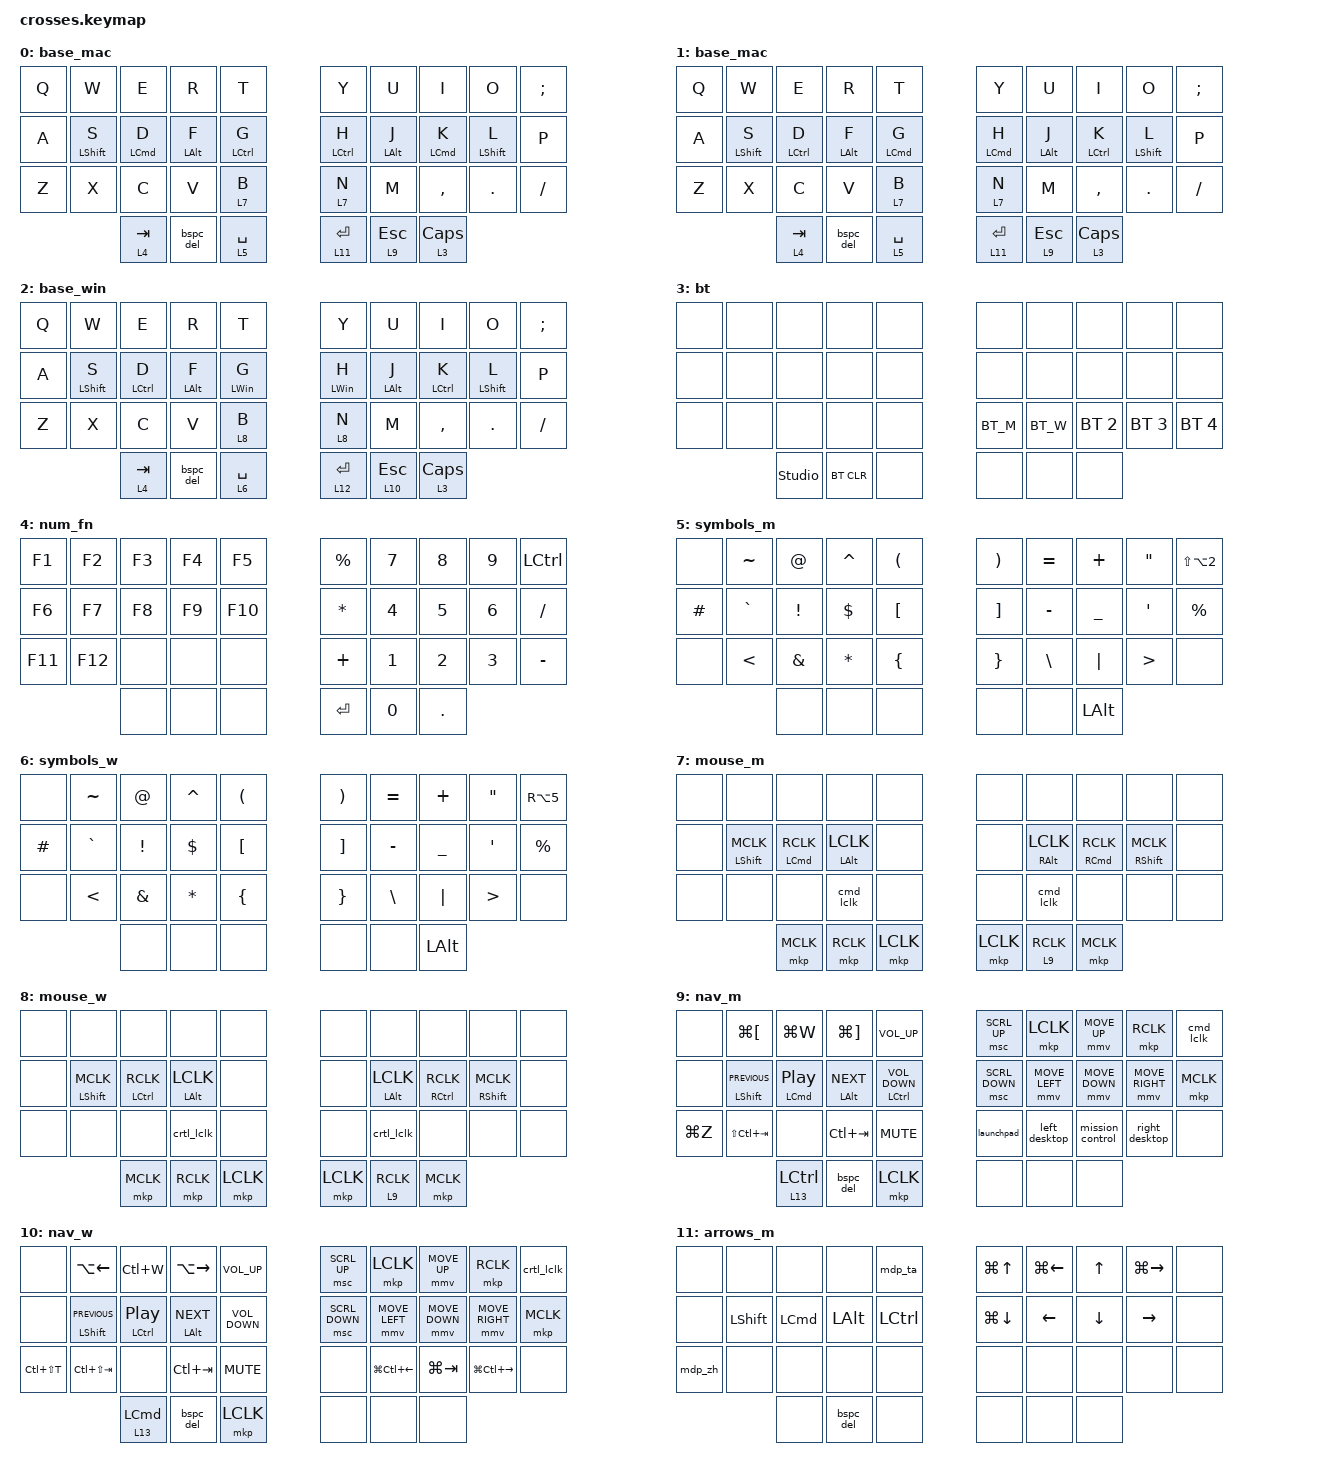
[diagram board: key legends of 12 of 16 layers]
/*
 * Copyright (c) 2020 The ZMK Contributors
 *
 * SPDX-License-Identifier: MIT
 */

#include <behaviors.dtsi>
#include <dt-bindings/zmk/bt.h>
#include <dt-bindings/zmk/keys.h>
#include <dt-bindings/zmk/pointing.h>

&caps_word { continue-list = <UNDERSCORE BACKSPACE DELETE RETURN SPACE>; };

/ {
    chosen { zmk,physical-layout = &gggw_crosses_36_layout; };

    combos {
        compatible = "zmk,combos";

        ctrl_alt_suppr {
            bindings = <&ctrl_alt_sppr>;
            key-positions = <7 3 2 6>;
            layers = <2 10>;
        };

        middle_click {
            bindings = <&mkp MCLK>;
            key-positions = <6 8>;
            layers = <9 10>;
        };

        base_mac_layer {
            bindings = <&to 0>;
            key-positions = <33 26>;
        };

        base_win_layer {
            bindings = <&to 2>;
            key-positions = <33 25>;
        };

        app_expose_m {
            bindings = <&app_expose>;
            key-positions = <27 26 28>;
            layers = <9>;
        };

        tog_micro {
            bindings = <&kp LG(LA(K))>;
            key-positions = <15 14>;
        };

        game_layer {
            bindings = <&to 15>;
            key-positions = <33 27>;
        };

        base_mac_vim {
            bindings = <&to 1>;
            key-positions = <33 25 26>;
        };
    };

    behaviors {
        hold_sitcky: hold_sitcky {
            compatible = "zmk,behavior-hold-tap";
            label = "HOLD_SITCKY";
            bindings = <&kp>, <&sk>;

            #binding-cells = <2>;
            tapping-term-ms = <200>;
            quick-tap-ms = <175>;
        };

        hold_to: hold_to {
            compatible = "zmk,behavior-hold-tap";
            label = "HOLD_TO";
            bindings = <&mo>, <&to>;

            #binding-cells = <2>;
            tapping-term-ms = <200>;
            quick-tap-ms = <175>;
            flavor = "balanced";
        };

        mo_sticky: mo_sticky {
            compatible = "zmk,behavior-hold-tap";
            label = "MO_STICKY";
            bindings = <&mo>, <&sk>;

            #binding-cells = <2>;
            tapping-term-ms = <200>;
            quick-tap-ms = <175>;
        };

        hmrl: hmrl {
            compatible = "zmk,behavior-hold-tap";
            label = "HMRL";
            bindings = <&kp>, <&kp>;

            #binding-cells = <2>;
            tapping-term-ms = <225>;
            quick-tap-ms = <200>;
            flavor = "tap-preferred";
        };

        hold_caps_word: hold_caps_word {
            compatible = "zmk,behavior-hold-tap";
            label = "HOLD_CAPS_WORD";
            bindings = <&mo>, <&kp>;

            #binding-cells = <2>;
            tapping-term-ms = <200>;
            quick-tap-ms = <175>;
            flavor = "balanced";
        };

        bspc_del: bspc_del {
            compatible = "zmk,behavior-mod-morph";
            label = "BSPC_DEL";
            bindings = <&kp BACKSPACE>, <&kp DELETE>;

            #binding-cells = <0>;
            mods = <(MOD_LSFT)>;
        };

        mo_mkp: mo_mkp {
            compatible = "zmk,behavior-hold-tap";
            label = "MO_MKP";
            bindings = <&mo>, <&mkp>;

            #binding-cells = <2>;
            tapping-term-ms = <200>;
            quick-tap-ms = <175>;
            flavor = "balanced";
        };

        hmr_mkp: hmr_mkp {
            compatible = "zmk,behavior-hold-tap";
            label = "HMR_MKP";
            bindings = <&kp>, <&mkp>;

            #binding-cells = <2>;
            tapping-term-ms = <225>;
            quick-tap-ms = <200>;
        };
    };

    macros {
        mission_control: mission_control {
            compatible = "zmk,behavior-macro";
            #binding-cells = <0>;
            bindings = <&kp LC(UP_ARROW)>;
            label = "Mission Control";
        };

        app_expose: app_expose {
            compatible = "zmk,behavior-macro";
            #binding-cells = <0>;
            bindings = <&kp LC(DOWN_ARROW)>;
            label = "App Expose";
        };

        left_desktop: left_desktop {
            compatible = "zmk,behavior-macro";
            #binding-cells = <0>;
            bindings = <&kp LC(LEFT_ARROW)>;
            label = "Left desktop";
        };

        right_desktop: right_desktop {
            compatible = "zmk,behavior-macro";
            #binding-cells = <0>;
            bindings = <&kp LC(RIGHT_ARROW)>;
            label = "Right desktop";
        };

        launchpad: launchpad {
            compatible = "zmk,behavior-macro";
            #binding-cells = <0>;
            bindings = <&kp LC(LS(UP_ARROW))>;
            label = "Launchpad";
        };

        ctrl_alt_sppr: ctrl_alt_sppr {
            compatible = "zmk,behavior-macro";
            #binding-cells = <0>;
            bindings = <&kp LA(LC(DELETE))>;
            label = "Ctrl+Alt+Suppr Windows";
        };

        start_line: start_line {
            compatible = "zmk,behavior-macro";
            #binding-cells = <0>;
            bindings = <&kp LG(LEFT_ARROW)>;
            label = "Start of line Mac";
        };

        end_line: end_line {
            compatible = "zmk,behavior-macro";
            #binding-cells = <0>;
            bindings = <&kp LG(RIGHT_ARROW)>;
            label = "End of line Mac";
        };

        BT_M: BT_M {
            compatible = "zmk,behavior-macro";
            #binding-cells = <0>;
            bindings = <&bt BT_SEL 0 &to 0>;
            label = "Bluetooth Mac";
        };

        BT_W: BT_W {
            compatible = "zmk,behavior-macro";
            #binding-cells = <0>;
            bindings = <&bt BT_SEL 1 &to 2>;
            label = "Bluetooth Windows";
        };

        cmd_lclk: cmd_lclk {
            compatible = "zmk,behavior-macro";
            #binding-cells = <0>;
            bindings =
                <&macro_press>,
                <&kp LEFT_COMMAND>,
                <&macro_tap>,
                <&mkp LCLK>,
                <&macro_release>,
                <&kp LEFT_COMMAND>;

            label = "Cmd+Left click";
        };

        crtl_lclk: crtl_lclk {
            compatible = "zmk,behavior-macro";
            #binding-cells = <0>;
            bindings =
                <&macro_press>,
                <&kp LEFT_CONTROL>,
                <&macro_tap>,
                <&mkp LCLK>,
                <&macro_release>,
                <&kp LEFT_CONTROL>;

            label = "Ctrl+Left click";
        };

        double_shift: double_shift {
            compatible = "zmk,behavior-macro";
            #binding-cells = <0>;
            bindings = <&kp LEFT_SHIFT &kp LEFT_SHIFT>;
            label = "DOUBLE_SHIFT";
        };

        mdp_zh: mdp_mac {
            compatible = "zmk,behavior-macro";
            #binding-cells = <0>;
            bindings = <&kp LS(Z) &kp A &kp H &kp A &kp LS(H) &kp A &kp D &kp I &kp D &kp N0 &kp N7 &kp EXCL>;
            label = "MDP_MAC";
        };

        mdp_ta: mdp_dash {
            compatible = "zmk,behavior-macro";
            #binding-cells = <0>;
            bindings = <&kp LS(T) &kp A &kp D &kp A &kp O &kp LS(A) &kp N &kp D &kp O &kp N0 &kp N7>;
            label = "MDP_DASH";
        };

        mdp_cap: mdp_cap {
            compatible = "zmk,behavior-macro";
            #binding-cells = <0>;
            bindings = <&kp LS(E) &kp S &kp M &kp E &kp E &kp LS(G) &kp U &kp I &kp L &kp L &kp O &kp U &kp N1 &kp N5 &kp EXCL>;
            label = "MDP_CAP";
        };
    };

    keymap {
        compatible = "zmk,keymap";

        base_mac {
            display-name = "base_mac";
            bindings = <
&kp Q  &kp W               &kp E                 &kp R             &kp T                 &kp Y                 &kp U             &kp I                 &kp O               &kp SEMICOLON
&kp A  &hmrl LEFT_SHIFT S  &hmrl LEFT_COMMAND D  &hmrl LEFT_ALT F  &hmrl LEFT_CONTROL G  &hmrl LEFT_CONTROL H  &hmrl LEFT_ALT J  &hmrl LEFT_COMMAND K  &hmrl LEFT_SHIFT L  &kp P
&kp Z  &kp X               &kp C                 &kp V             &lt 7 B               &lt 7 N               &kp M             &kp COMMA             &kp DOT             &kp FSLH
                           &lt 4 TAB             &bspc_del         &lt 5 SPACE           &lt 11 RETURN         &lt 9 ESCAPE      &lt 3 CAPSLOCK
            >;
        };

        base_mac_vim {
            display-name = "base_mac";
            bindings = <
&kp Q  &kp W               &kp E                 &kp R             &kp T                 &kp Y                 &kp U             &kp I                 &kp O               &kp SEMICOLON
&kp A  &hmrl LEFT_SHIFT S  &hmrl LEFT_CONTROL D  &hmrl LEFT_ALT F  &hmrl LEFT_COMMAND G  &hmrl LEFT_COMMAND H  &hmrl LEFT_ALT J  &hmrl LEFT_CONTROL K  &hmrl LEFT_SHIFT L  &kp P
&kp Z  &kp X               &kp C                 &kp V             &lt 7 B               &lt 7 N               &kp M             &kp COMMA             &kp DOT             &kp FSLH
                           &lt 4 TAB             &bspc_del         &lt 5 SPACE           &lt 11 RETURN         &lt 9 ESCAPE      &lt 3 CAPSLOCK
            >;

            label = "base_mac_vim";
        };

        base_win {
            display-name = "base_win";
            bindings = <
&kp Q  &kp W               &kp E                 &kp R             &kp T             &kp Y             &kp U             &kp I                 &kp O               &kp SEMICOLON
&kp A  &hmrl LEFT_SHIFT S  &hmrl LEFT_CONTROL D  &hmrl LEFT_ALT F  &hmrl LEFT_WIN G  &hmrl LEFT_WIN H  &hmrl LEFT_ALT J  &hmrl LEFT_CONTROL K  &hmrl LEFT_SHIFT L  &kp P
&kp Z  &kp X               &kp C                 &kp V             &lt 8 B           &lt 8 N           &kp M             &kp COMMA             &kp DOT             &kp FSLH
                           &lt 4 TAB             &bspc_del         &lt 6 SPACE       &lt 12 RETURN     &lt 10 ESCAPE     &lt 3 CAPSLOCK
            >;
        };

        bt {
            display-name = "bt";
            bindings = <
&none  &none  &none           &none       &none  &none  &none  &none         &none         &none
&none  &none  &none           &none       &none  &none  &none  &none         &none         &none
&none  &none  &none           &none       &none  &BT_M  &BT_W  &bt BT_SEL 2  &bt BT_SEL 3  &bt BT_SEL 4
              &studio_unlock  &bt BT_CLR  &none  &none  &none  &none
            >;
        };

        num_fn {
            display-name = "num_fn";
            bindings = <
&kp F1   &kp F2   &kp F3  &kp F4  &kp F5   &kp PERCENT   &kp N7        &kp N8      &kp N9  &kp LCTRL
&kp F6   &kp F7   &kp F8  &kp F9  &kp F10  &kp ASTERISK  &kp N4        &kp N5      &kp N6  &kp FSLH
&kp F11  &kp F12  &none   &none   &none    &kp PLUS      &kp N1        &kp N2      &kp N3  &kp MINUS
                  &none   &none   &none    &kp RET       &kp NUMBER_0  &kp PERIOD
            >;
        };

        symbols_m {
            display-name = "symbols_m";
            bindings = <
&none     &kp TILDE      &kp AT_SIGN      &kp CARET     &kp LEFT_PARENTHESIS  &kp RIGHT_PARENTHESIS  &kp EQUAL      &kp PLUS        &kp DOUBLE_QUOTES  &kp LS(LA(NUMBER_2))
&kp HASH  &kp GRAVE      &kp EXCLAMATION  &kp DOLLAR    &kp LEFT_BRACKET      &kp RIGHT_BRACKET      &kp MINUS      &kp UNDERSCORE  &kp APOSTROPHE     &kp PERCENT
&none     &kp LESS_THAN  &kp AMPERSAND    &kp ASTERISK  &kp LEFT_BRACE        &kp RIGHT_BRACE        &kp BACKSLASH  &kp PIPE        &kp GREATER_THAN   &none
                         &none            &none         &none                 &none                  &none          &kp LEFT_ALT
            >;
        };

        symbols_w {
            display-name = "symbols_w";
            bindings = <
&none     &kp TILDE      &kp AT           &kp CARET     &kp LEFT_PARENTHESIS  &kp RIGHT_PARENTHESIS  &kp EQUAL  &kp PLUS        &kp DOUBLE_QUOTES  &kp RA(NUMBER_5)
&kp HASH  &kp GRAVE      &kp EXCLAMATION  &kp DOLLAR    &kp LBKT              &kp RBKT               &kp MINUS  &kp UNDERSCORE  &kp APOSTROPHE     &kp PERCENT
&none     &kp LESS_THAN  &kp AMPERSAND    &kp ASTERISK  &kp LEFT_BRACE        &kp RIGHT_BRACE        &kp BSLH   &kp PIPE        &kp GREATER_THAN   &none
                         &none            &none         &none                 &none                  &none      &kp LEFT_ALT
            >;
        };

        mouse_m {
            bindings = <
&none  &none                     &none                       &none                   &none      &none      &none                    &none                        &none                 &none
&none  &hmr_mkp LEFT_SHIFT MCLK  &hmr_mkp LEFT_COMMAND RCLK  &hmr_mkp LEFT_ALT LCLK  &none      &none      &hmr_mkp RIGHT_ALT LCLK  &hmr_mkp RIGHT_COMMAND RCLK  &hmr_mkp RSHIFT MCLK  &none
&none  &none                     &none                       &cmd_lclk               &none      &none      &cmd_lclk                &none                        &none                 &none
                                 &mkp MCLK                   &mkp RCLK               &mkp LCLK  &mkp LCLK  &mo_mkp 9 RCLK           &mkp MCLK
            >;

            label = "mouse_m";
        };

        mouse_w {
            label = "mouse_w";
            bindings = <
&none  &none                     &none                       &none                   &none      &none      &none                   &none                        &none                      &none
&none  &hmr_mkp LEFT_SHIFT MCLK  &hmr_mkp LEFT_CONTROL RCLK  &hmr_mkp LEFT_ALT LCLK  &none      &none      &hmr_mkp LEFT_ALT LCLK  &hmr_mkp RIGHT_CONTROL RCLK  &hmr_mkp RIGHT_SHIFT MCLK  &none
&none  &none                     &none                       &crtl_lclk              &none      &none      &crtl_lclk              &none                        &none                      &none
                                 &mkp MCLK                   &mkp RCLK               &mkp LCLK  &mkp LCLK  &mo_mkp 9 RCLK          &mkp MCLK
            >;
        };

        nav_m {
            display-name = "nav_m";
            bindings = <
&none      &kp LG(LEFT_BRACKET)         &kp LG(W)                        &kp LG(RIGHT_BRACKET)  &kp C_VOLUME_UP            &msc SCRL_UP    &mkp LCLK       &mmv MOVE_UP      &mkp RCLK        &cmd_lclk
&none      &hmrl LEFT_SHIFT C_PREVIOUS  &hmrl LEFT_COMMAND C_PLAY_PAUSE  &hmrl LEFT_ALT C_NEXT  &hmrl LCTRL C_VOLUME_DOWN  &msc SCRL_DOWN  &mmv MOVE_LEFT  &mmv MOVE_DOWN    &mmv MOVE_RIGHT  &mkp MCLK
&kp LG(Z)  &kp LS(LC(TAB))              &none                            &kp LC(TAB)            &kp C_MUTE                 &launchpad      &left_desktop   &mission_control  &right_desktop   &none
                                        &mo_sticky 13 LEFT_CONTROL       &bspc_del              &mkp LCLK                  &none           &none           &none
            >;
        };

        nav_w {
            display-name = "nav_w";
            bindings = <
&none          &kp LA(LEFT_ARROW)           &kp LC(W)                        &kp LA(RIGHT_ARROW)    &kp C_VOLUME_UP    &msc SCRL_UP    &mkp LCLK               &mmv MOVE_UP    &mkp RCLK                &crtl_lclk
&none          &hmrl LEFT_SHIFT C_PREVIOUS  &hmrl LEFT_CONTROL C_PLAY_PAUSE  &hmrl LEFT_ALT C_NEXT  &kp C_VOLUME_DOWN  &msc SCRL_DOWN  &mmv MOVE_LEFT          &mmv MOVE_DOWN  &mmv MOVE_RIGHT          &mkp MCLK
&kp LC(LS(T))  &kp LC(LS(TAB))              &none                            &kp LC(TAB)            &kp C_MUTE         &none           &kp LG(LC(LEFT_ARROW))  &kp LG(TAB)     &kp LG(LC(RIGHT_ARROW))  &none
                                            &mo_sticky 13 LEFT_COMMAND       &bspc_del              &mkp LCLK          &none           &none                   &none
            >;
        };

        arrows_m {
            display-name = "arrows_m";
            bindings = <
&none    &none           &none             &none         &mdp_ta           &kp LG(UP_ARROW)    &kp LG(LEFT_ARROW)  &kp UP_ARROW    &kp LG(RIGHT_ARROW)  &none
&none    &kp LEFT_SHIFT  &kp LEFT_COMMAND  &kp LEFT_ALT  &kp LEFT_CONTROL  &kp LG(DOWN_ARROW)  &kp LEFT_ARROW      &kp DOWN_ARROW  &kp RIGHT_ARROW      &none
&mdp_zh  &none           &none             &none         &none             &none               &none               &none           &none                &none
                         &none             &bspc_del     &none             &none               &none               &none
            >;
        };

        arrows_w {
            display-name = "arrows_w";
            bindings = <
&none     &none           &none             &none         &none         &kp LC(HOME)  &kp HOME        &kp UP_ARROW    &kp END          &none
&none     &kp LEFT_SHIFT  &kp LEFT_CONTROL  &kp LEFT_ALT  &kp LEFT_WIN  &kp LC(END)   &kp LEFT_ARROW  &kp DOWN_ARROW  &kp RIGHT_ARROW  &none
&mdp_cap  &none           &none             &none         &none         &none         &none           &none           &none            &none
                          &none             &bspc_del     &none         &none         &none           &none
            >;
        };

        cmd {
            display-name = "cmd";
            bindings = <
&none      &none      &none      &none      &none  &msc SCRL_UP    &cmd_lclk       &none  &none            &none
&kp LG(A)  &kp LG(S)  &none      &kp LG(F)  &none  &msc SCRL_DOWN  &msc SCRL_LEFT  &none  &msc SCRL_RIGHT  &none
&kp LG(Z)  &kp LG(X)  &kp LG(C)  &kp LG(V)  &none  &none           &none           &none  &none            &none
                      &none      &none      &none  &none           &none           &none
            >;
        };

        ctrl {
            display-name = "ctrl";
            bindings = <
&none      &none      &none      &none      &none  &msc SCRL_UP    &crtl_lclk      &none  &none            &none
&kp LC(A)  &kp LC(S)  &none      &kp LC(F)  &none  &msc SCRL_DOWN  &msc SCRL_LEFT  &none  &msc SCRL_RIGHT  &none
&kp LC(Z)  &kp LC(X)  &kp LC(C)  &kp LC(V)  &none  &none           &none           &none  &none            &none
                      &none      &none      &none  &none           &none           &none
            >;
        };

        game {
            display-name = "game";
            bindings = <
&kp Q  &kp W  &kp E    &kp R             &kp T      &kp ESCAPE      &none      &kp UP_ARROW  &kp O      &none
&kp A  &kp S  &kp D    &kp F             &kp G      &kp LEFT_SHIFT  &kp LEFT   &kp DOWN      &kp RIGHT  &kp P
&kp Z  &kp X  &kp C    &kp V             &kp B      &kp N           &kp M      &none         &none      &none
              &kp TAB  &kp LEFT_CONTROL  &kp SPACE  &mkp LCLK       &mkp RCLK  &mkp MCLK
            >;
        };
    };
};
